AUTOSAR XML (schema 00053)
package /Services
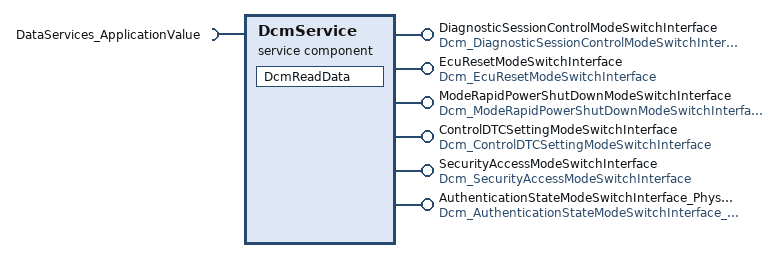
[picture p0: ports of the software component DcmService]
  service sw component type DcmService
    require port DataServices_ApplicationValue: client-com-spec=ReadData, required-interface=DataServices_ApplicationValue
    6 x provide port:
      DiagnosticSessionControlModeSwitchInterface: mode-switch-sender-com-spec{enhanced-mode-api=false, mode-group=diagnosticSession}, provided-interface=Dcm_DiagnosticSessionControlModeSwitchInterface
      EcuResetModeSwitchInterface: mode-switch-sender-com-spec{enhanced-mode-api=false, mode-group=ecuReset}, provided-interface=Dcm_EcuResetModeSwitchInterface
      ModeRapidPowerShutDownModeSwitchInterface: mode-switch-sender-com-spec{enhanced-mode-api=false, mode-group=modeRapidPowerShutDown}, provided-interface=Dcm_ModeRapidPowerShutDownModeSwitchInterface
      ControlDTCSettingModeSwitchInterface: mode-switch-sender-com-spec{enhanced-mode-api=false, mode-group=controlDTCSetting}, provided-interface=Dcm_ControlDTCSettingModeSwitchInterface
      SecurityAccessModeSwitchInterface: mode-switch-sender-com-spec{enhanced-mode-api=false, mode-group=securityAccess}, provided-interface=Dcm_SecurityAccessModeSwitchInterface
      AuthenticationStateModeSwitchInterface_Physical: mode-switch-sender-com-spec{enhanced-mode-api=false, mode-group=authenticationState}, provided-interface=Dcm_AuthenticationStateModeSwitchInterface_Physical
    behavior Behavior: data-type-mapping=DcmModeTypes
      runnable DcmReadData: symbol=DcmService_ReadData
        sync call ReadApplicationValue: operation=DataServices_ApplicationValue.ReadData
  mode switch interface Dcm_DiagnosticSessionControlModeSwitchInterface: is-service=true
    mode group diagnosticSession: type=DcmDiagnosticSessionControl
  data type mapping set DcmModeTypes
    mode-request-type-maps:
      implementation-data-type=Rte_ModeType_DcmDiagnosticSessionControl, mode-group=DcmDiagnosticSessionControl
      implementation-data-type=Rte_ModeType_DcmEcuReset, mode-group=DcmEcuReset
      implementation-data-type=Rte_ModeType_DcmModeRapidPowerShutDown, mode-group=DcmModeRapidPowerShutDown
      implementation-data-type=Rte_ModeType_DcmControlDTCSetting, mode-group=DcmControlDTCSetting
      implementation-data-type=Rte_ModeType_DcmSecurityAccess, mode-group=DcmSecurityAccess
      implementation-data-type=Rte_ModeType_DcmAuthenticationState_Physical, mode-group=DcmAuthenticationState_Physical
  5 x mode switch interface, all with is-service=true:
    Dcm_EcuResetModeSwitchInterface
      mode group ecuReset: type=DcmEcuReset
    Dcm_ModeRapidPowerShutDownModeSwitchInterface
      mode group modeRapidPowerShutDown: type=DcmModeRapidPowerShutDown
    Dcm_ControlDTCSettingModeSwitchInterface
      mode group controlDTCSetting: type=DcmControlDTCSetting
    Dcm_SecurityAccessModeSwitchInterface
      mode group securityAccess: type=DcmSecurityAccess
    Dcm_AuthenticationStateModeSwitchInterface_Physical
      mode group authenticationState: type=DcmAuthenticationState_Physical
